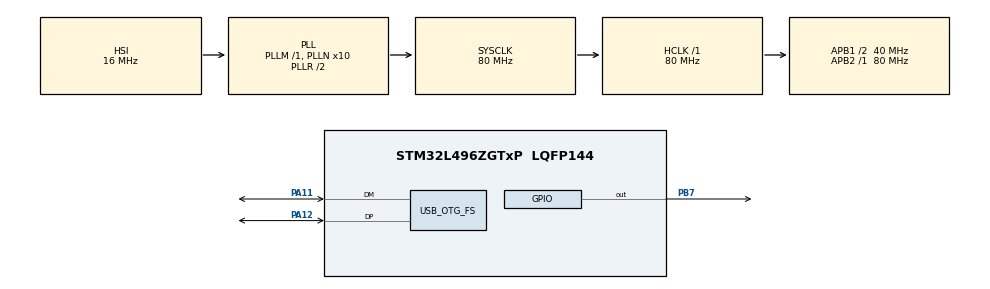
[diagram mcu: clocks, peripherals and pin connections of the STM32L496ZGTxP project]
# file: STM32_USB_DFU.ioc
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Mcu.Family=STM32L4
Mcu.Name=STM32L496ZGTxP
Mcu.Package=LQFP144
NVIC.OTG_FS_IRQn=true\:0\:0\:false\:false\:true\:false\:true\:true
NVIC.PriorityGroup=NVIC_PRIORITYGROUP_4
PA11.Mode=Device_Only
PA11.Signal=USB_OTG_FS_DM
PA12.Mode=Device_Only
PA12.Signal=USB_OTG_FS_DP
PA13\ (JTMS/SWDIO).Mode=Serial_Wire
PA13\ (JTMS/SWDIO).Signal=SYS_JTMS-SWDIO
PA14\ (JTCK/SWCLK).Mode=Serial_Wire
PA14\ (JTCK/SWCLK).Signal=SYS_JTCK-SWCLK
PB7.Signal=GPIO_Output
ProjectManager.HeapSize=0x200
ProjectManager.StackSize=0x400
ProjectManager.TargetToolchain=STM32CubeIDE
RCC.48MHZClocksFreq_Value=24000000
RCC.ADCFreq_Value=64000000
RCC.AHBFreq_Value=80000000
RCC.APB1CLKDivider=RCC_HCLK_DIV2
RCC.APB1Freq_Value=40000000
RCC.APB1TimFreq_Value=80000000
RCC.APB2Freq_Value=80000000
RCC.APB2TimFreq_Value=80000000
RCC.CK48CLockSelection=RCC_USBCLKSOURCE_HSI48
RCC.CortexFreq_Value=80000000
RCC.HCLKFreq_Value=80000000
RCC.HSE_VALUE=8000000
RCC.HSI48_VALUE=48000000
RCC.HSI_VALUE=16000000
RCC.LSE_VALUE=32768
RCC.MSI_VALUE=4000000
RCC.PLLMUL=RCC_PLL_MUL9
RCC.PLLN=10
RCC.PLLSourceVirtual=RCC_PLLSOURCE_HSI
RCC.PRESCALERUSB=RCC_USBCLKSOURCE_PLL_DIV1_5
RCC.SYSCLKFreq_VALUE=80000000
RCC.SYSCLKSource=RCC_SYSCLKSOURCE_PLLCLK
RCC.SYSCLKSourceVirtual=RCC_SYSCLKSOURCE_PLLCLK
RCC.USBFreq_Value=48000000
RCC.VCOOutputFreq_Value=160000000
USB_DEVICE.CLASS_NAME_FS=CDC
USB_DEVICE.VirtualMode=Cdc
USB_DEVICE.VirtualModeFS=Cdc_FS
USB_OTG_FS.VirtualMode=Device_Only
VP_USB_DEVICE_VS_USB_DEVICE_CDC_FS.Mode=CDC_FS
board=NUCLEO-L496ZG-P

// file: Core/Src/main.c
/* USER CODE BEGIN Header */
/**
  ******************************************************************************
  * @file           : main.c
  * @brief          : Main program body
  ******************************************************************************
  * @attention
  *
  * Copyright (c) 2026 STMicroelectronics.
  * All rights reserved.
  *
  * This software is licensed under terms that can be found in the LICENSE file
  * in the root directory of this software component.
  * If no LICENSE file comes with this software, it is provided AS-IS.
  *
  ******************************************************************************
  */
/* USER CODE END Header */
#include "main.h"
#include "usb_device.h"

/* USER CODE BEGIN Includes */
#include "usbd_cdc_if.h"
#include "stdio.h"
/* USER CODE END Includes */

void SystemClock_Config(void);
static void MX_GPIO_Init(void);

/* USER CODE BEGIN 0 */

int _write(int file, char *ptr, int len)
{
    while (CDC_Transmit_FS((uint8_t *)ptr, len) == USBD_BUSY)
    {
        HAL_Delay(1);
    }
    return len;
}

void jumpToBootloader(void)
{
    void (*SysMemBootJump)(void);

#define SYS_MEM_ADDRESS 0x1FFF0000U

    __disable_irq();

    SysTick->CTRL = 0;
    SysTick->LOAD = 0;
    SysTick->VAL  = 0;

    /* Remap system memory to 0x00000000 */
    __HAL_SYSCFG_REMAPMEMORY_SYSTEMFLASH();

    SysMemBootJump = (void (*)(void))(*((uint32_t *)(SYS_MEM_ADDRESS + 4)));
    __set_MSP(*(uint32_t *)SYS_MEM_ADDRESS);

    __enable_irq();

    SysMemBootJump();
    while(1);
}

/* USER CODE END 0 */

int main(void)
{

  /* USER CODE BEGIN 1 */

	__HAL_RCC_PWR_CLK_ENABLE();
	HAL_PWR_EnableBkUpAccess();
	if (RTC->BKP0R == 0x1234)
	{
		RTC->BKP0R = 0;
		jumpToBootloader();
	}

  /* USER CODE END 1 */

  /* MCU Configuration--------------------------------------------------------*/

  /* Reset of all peripherals, Initializes the Flash interface and the Systick. */
  HAL_Init();

  /* Configure the system clock */
  SystemClock_Config();

  /* Initialize all configured peripherals */
  MX_GPIO_Init();
  MX_USB_DEVICE_Init();

  /* Infinite loop */
  while (1)
  {

    /* USER CODE BEGIN 3 */

	  HAL_GPIO_TogglePin(GPIOB, GPIO_PIN_7);
	  printf ("Running Test 3..\r\n");
	  HAL_Delay(100);
  }
  /* USER CODE END 3 */
}

void SystemClock_Config(void)
{
  RCC_OscInitTypeDef RCC_OscInitStruct = {0};
  RCC_ClkInitTypeDef RCC_ClkInitStruct = {0};

  /** Configure the main internal regulator output voltage
  */
  if (HAL_PWREx_ControlVoltageScaling(PWR_REGULATOR_VOLTAGE_SCALE1) != HAL_OK)
  {
    Error_Handler();
  }

  /** Initializes the RCC Oscillators according to the specified parameters
  * in the RCC_OscInitTypeDef structure.
  */
  RCC_OscInitStruct.OscillatorType = RCC_OSCILLATORTYPE_HSI48|RCC_OSCILLATORTYPE_HSI;
  RCC_OscInitStruct.HSIState = RCC_HSI_ON;
  RCC_OscInitStruct.HSI48State = RCC_HSI48_ON;
  RCC_OscInitStruct.HSICalibrationValue = RCC_HSICALIBRATION_DEFAULT;
  RCC_OscInitStruct.PLL.PLLState = RCC_PLL_ON;
  RCC_OscInitStruct.PLL.PLLSource = RCC_PLLSOURCE_HSI;
  RCC_OscInitStruct.PLL.PLLM = 1;
  RCC_OscInitStruct.PLL.PLLN = 10;
  RCC_OscInitStruct.PLL.PLLP = RCC_PLLP_DIV2;
  RCC_OscInitStruct.PLL.PLLQ = RCC_PLLQ_DIV2;
  RCC_OscInitStruct.PLL.PLLR = RCC_PLLR_DIV2;
  if (HAL_RCC_OscConfig(&RCC_OscInitStruct) != HAL_OK)
  {
    Error_Handler();
  }

  /** Initializes the CPU, AHB and APB buses clocks
  */
  RCC_ClkInitStruct.ClockType = RCC_CLOCKTYPE_HCLK|RCC_CLOCKTYPE_SYSCLK
                              |RCC_CLOCKTYPE_PCLK1|RCC_CLOCKTYPE_PCLK2;
  RCC_ClkInitStruct.SYSCLKSource = RCC_SYSCLKSOURCE_PLLCLK;
  RCC_ClkInitStruct.AHBCLKDivider = RCC_SYSCLK_DIV1;
  RCC_ClkInitStruct.APB1CLKDivider = RCC_HCLK_DIV2;
  RCC_ClkInitStruct.APB2CLKDivider = RCC_HCLK_DIV1;

  if (HAL_RCC_ClockConfig(&RCC_ClkInitStruct, FLASH_LATENCY_4) != HAL_OK)
  {
    Error_Handler();
  }
}

static void MX_GPIO_Init(void)
{
  GPIO_InitTypeDef GPIO_InitStruct = {0};

  /* GPIO Ports Clock Enable */
  __HAL_RCC_GPIOA_CLK_ENABLE();
  __HAL_RCC_GPIOB_CLK_ENABLE();

  /*Configure GPIO pin Output Level */
  HAL_GPIO_WritePin(GPIOB, GPIO_PIN_7, GPIO_PIN_RESET);

  /*Configure GPIO pin : PB7 */
  GPIO_InitStruct.Pin = GPIO_PIN_7;
  GPIO_InitStruct.Mode = GPIO_MODE_OUTPUT_PP;
  GPIO_InitStruct.Pull = GPIO_NOPULL;
  GPIO_InitStruct.Speed = GPIO_SPEED_FREQ_LOW;
  HAL_GPIO_Init(GPIOB, &GPIO_InitStruct);

}

void Error_Handler(void)
{
  __disable_irq();
  while (1)
  {
  }
}
